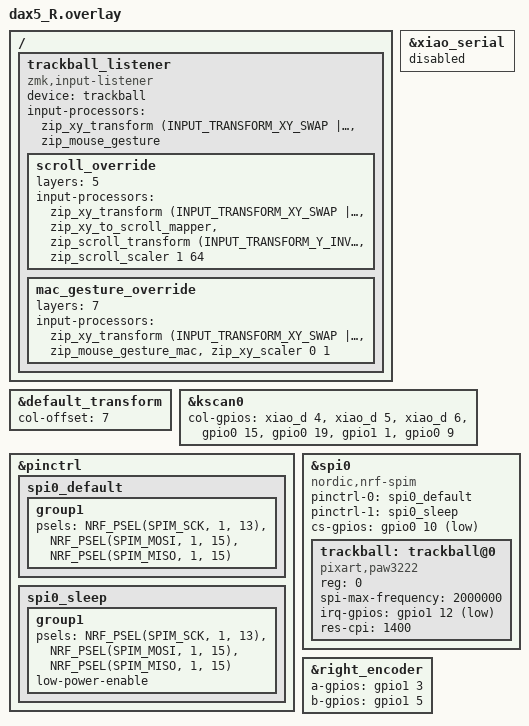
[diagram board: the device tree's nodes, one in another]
#include "dax5.dtsi"
#include <input/processors.dtsi>
#include <dt-bindings/zmk/input_transform.h>

&xiao_serial {
  status = "disabled";
};

&default_transform {
  col-offset = <7>;
};

&kscan0 {
  col-gpios
    = <&xiao_d 4 GPIO_ACTIVE_HIGH> // D4/P0.04 -> Col0
    , <&xiao_d 5 GPIO_ACTIVE_HIGH> // D5/P0.05 -> Col1
    , <&xiao_d 6 GPIO_ACTIVE_HIGH> // D6/P1.11 -> Col2
    , <&gpio0 15 GPIO_ACTIVE_HIGH> // P0.15 -> Col3
    , <&gpio0 19 GPIO_ACTIVE_HIGH> // P0.19 -> Col4
    , <&gpio1 1 GPIO_ACTIVE_HIGH>  // P1.01 -> Col5
    , <&gpio0 9 GPIO_ACTIVE_HIGH>  // GP 0.09 -> Col6
    ;
};

/ {
  trackball_listener {
    compatible = "zmk,input-listener";
    device = <&trackball>;
    input-processors = <&zip_xy_transform (INPUT_TRANSFORM_XY_SWAP | INPUT_TRANSFORM_Y_INVERT)>, <&zip_mouse_gesture>;

    scroll_override {
      layers = <5>;  // SCROLL layer
      input-processors
        = <&zip_xy_transform (INPUT_TRANSFORM_XY_SWAP | INPUT_TRANSFORM_Y_INVERT)>
        , <&zip_xy_to_scroll_mapper>
        , <&zip_scroll_transform (INPUT_TRANSFORM_Y_INVERT)>
        , <&zip_scroll_scaler 1 64>
        ;
    };

    mac_gesture_override {
      layers = <7>;  // MAC_GESTURE layer
      input-processors
        = <&zip_xy_transform (INPUT_TRANSFORM_XY_SWAP | INPUT_TRANSFORM_Y_INVERT)>
        , <&zip_mouse_gesture_mac>
        , <&zip_xy_scaler 0 1>
        ;
    };
  };
};

&pinctrl {
  spi0_default: spi0_default {
    group1 {
      psels = <NRF_PSEL(SPIM_SCK, 1, 13)>, // P1.13 (D8/SCLK)
        <NRF_PSEL(SPIM_MOSI, 1, 15)>,      // P1.15 (D10/SDIO)
        <NRF_PSEL(SPIM_MISO, 1, 15)>;      // P1.15 (D10/SDIO)
    };
  };

  spi0_sleep: spi0_sleep {
    group1 {
      psels = <NRF_PSEL(SPIM_SCK, 1, 13)>,
        <NRF_PSEL(SPIM_MOSI, 1, 15)>,
        <NRF_PSEL(SPIM_MISO, 1, 15)>;
      low-power-enable;
    };
  };
};

&spi0 {
  status = "okay";
  compatible = "nordic,nrf-spim";
  pinctrl-0 = <&spi0_default>;
  pinctrl-1 = <&spi0_sleep>;
  pinctrl-names = "default", "sleep";
  cs-gpios = <&gpio0 10 GPIO_ACTIVE_LOW>;  // P0.10 (CS)

  trackball: trackball@0 {
    status = "okay";
    compatible = "pixart,paw3222";
    reg = <0>;
    spi-max-frequency = <2000000>;
    irq-gpios = <&gpio1 12 (GPIO_ACTIVE_LOW | GPIO_PULL_UP)>;  // P1.12 (D7/MOTION)
    res-cpi = <1400>;
  };
};

&right_encoder {
  a-gpios = <&gpio1 3 (GPIO_ACTIVE_HIGH | GPIO_PULL_UP)>;  // P1.03/RE_A
  b-gpios = <&gpio1 5 (GPIO_ACTIVE_HIGH | GPIO_PULL_UP)>;  // P1.05/RE_B
  status = "okay";
};
